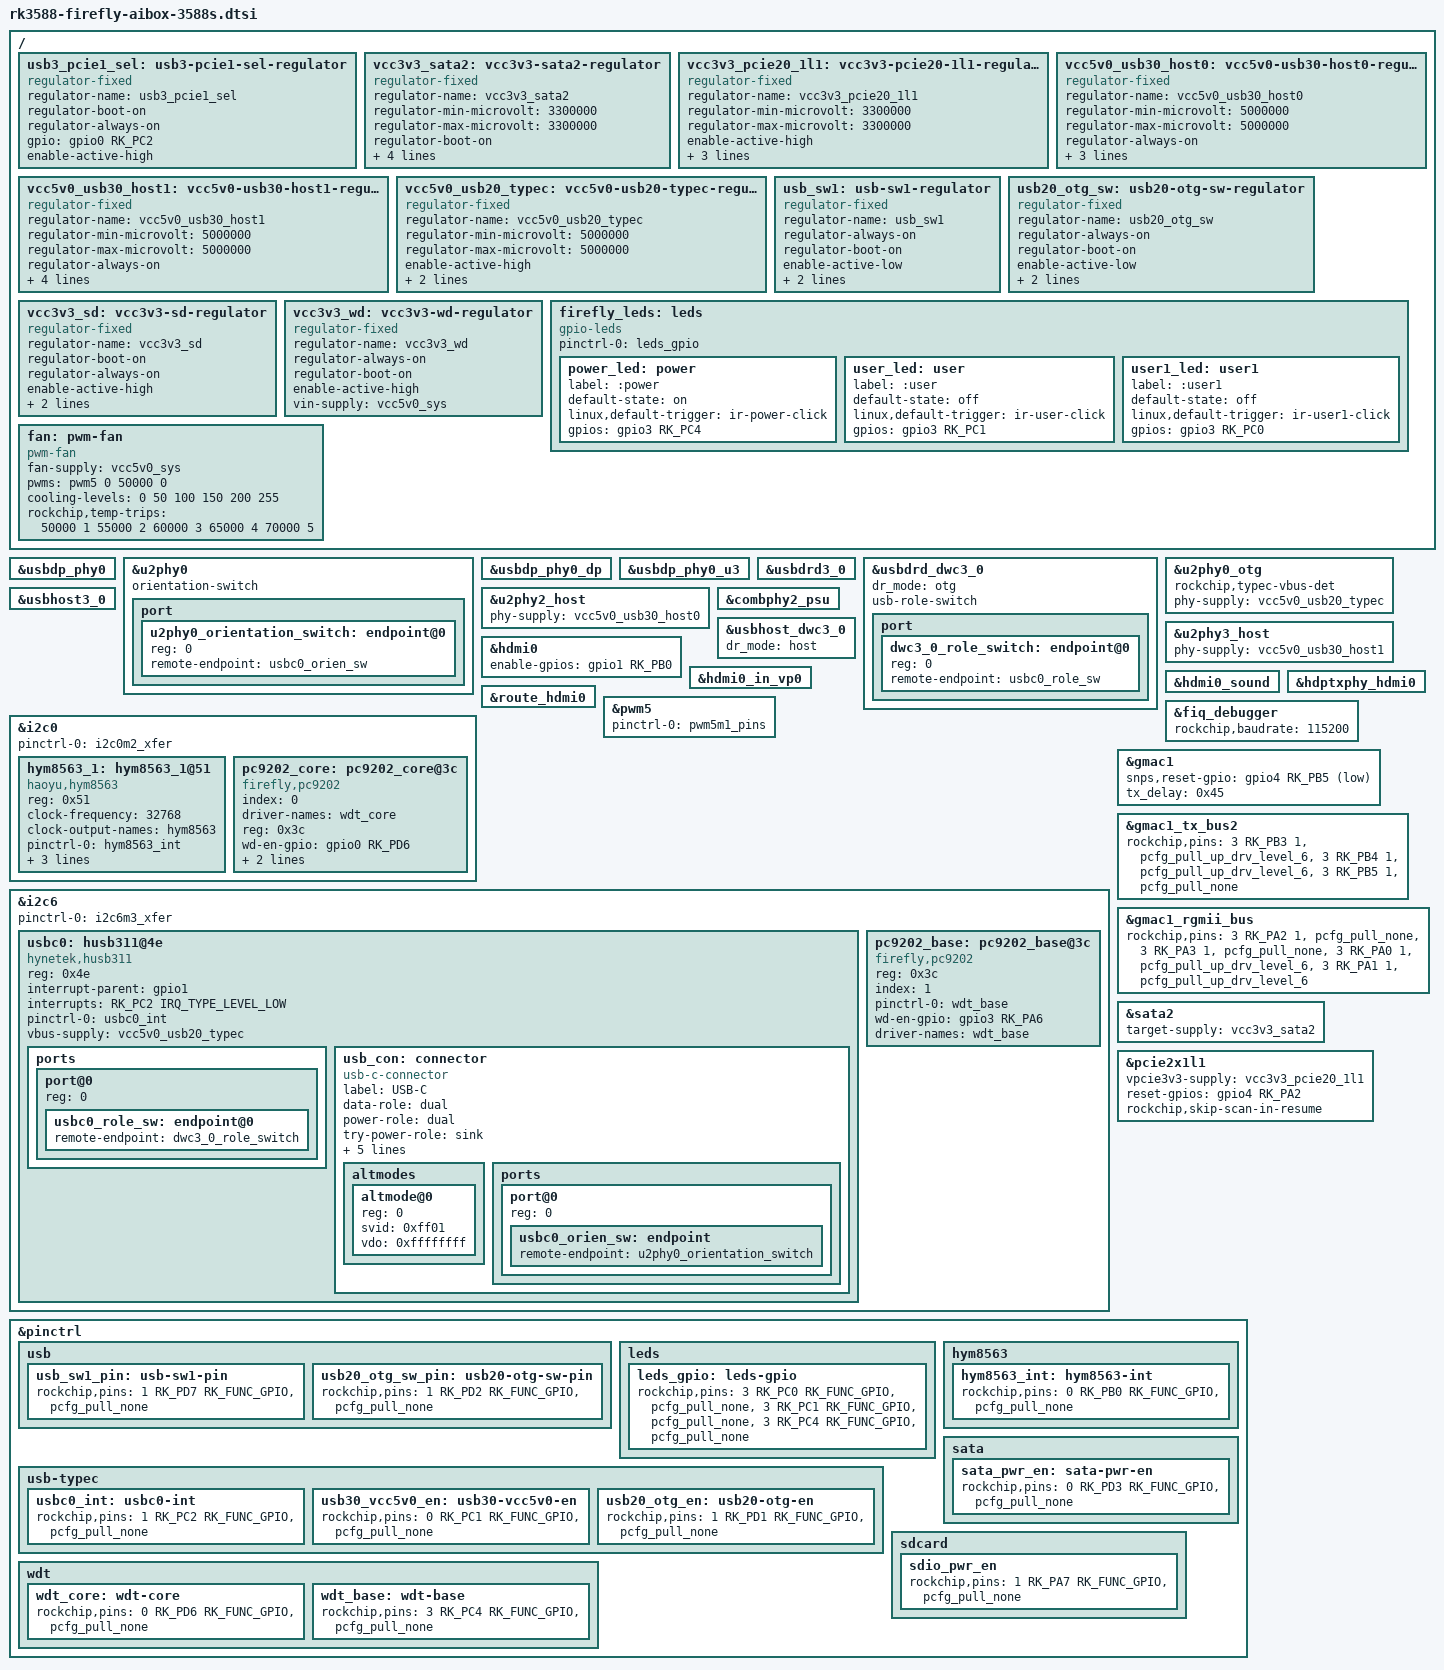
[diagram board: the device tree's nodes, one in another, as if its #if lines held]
// SPDX-License-Identifier: (GPL-2.0+ OR MIT)
/*
 * Copyright (c) 2021 Rockchip Electronics Co., Ltd.
 *
 */
 
#include "rk3588-firefly-common.dtsi"

/ {
	usb3_pcie1_sel: usb3-pcie1-sel-regulator {
		status = "okay";
		compatible = "regulator-fixed";
		regulator-name = "usb3_pcie1_sel";
		regulator-boot-on;
                regulator-always-on;
		gpio = <&gpio0 RK_PC2 GPIO_ACTIVE_HIGH>;

#if USB3_OR_M2_SLOT /* 1 = USB3 , 0 = M2_SLOT */
		enable-active-high;
#else
		enable-active-low;
#endif
	};

#if defined(FF_SATA2) && !defined(FF_PCIE2_1L1)
	vcc3v3_sata2: vcc3v3-sata2-regulator {
		status = "okay";
		compatible = "regulator-fixed";
		regulator-name = "vcc3v3_sata2";
		regulator-min-microvolt = <3300000>;
		regulator-max-microvolt = <3300000>;
		regulator-boot-on;
		enable-active-high;
		gpio = <&gpio0 RK_PD3 GPIO_ACTIVE_HIGH>;
		startup-delay-us = <5000>;
		vin-supply = <&vcc12v_dcin>;
	};
#endif

#if defined(FF_PCIE2_1L1) && !defined(FF_SATA2)
	vcc3v3_pcie20_1l1: vcc3v3-pcie20-1l1-regulator {
		status = "okay";
		compatible = "regulator-fixed";
		regulator-name = "vcc3v3_pcie20_1l1";
		regulator-min-microvolt = <3300000>;
		regulator-max-microvolt = <3300000>;
		enable-active-high;
		gpio = <&gpio0 RK_PD3 GPIO_ACTIVE_HIGH>;
		startup-delay-us = <5000>;
		vin-supply = <&vcc12v_dcin>;
	};
#endif

 	vcc5v0_usb30_host0: vcc5v0-usb30-host0-regulator {
  		compatible = "regulator-fixed";
                regulator-name = "vcc5v0_usb30_host0";
                regulator-min-microvolt = <5000000>;
                regulator-max-microvolt = <5000000>;
                regulator-always-on;
                regulator-boot-on;
                enable-active-high;
                pinctrl-names = "default";
		vin-supply = <&vcc5v0_usb30_host1>;
                status = "okay";
 	};

 	vcc5v0_usb30_host1: vcc5v0-usb30-host1-regulator {
  		compatible = "regulator-fixed";
                regulator-name = "vcc5v0_usb30_host1";
                regulator-min-microvolt = <5000000>;
                regulator-max-microvolt = <5000000>;
                regulator-always-on;
                regulator-boot-on;
                enable-active-high;
                gpio = <&gpio0 RK_PC1 GPIO_ACTIVE_HIGH>;
                pinctrl-names = "default";
                pinctrl-0 = <&usb30_vcc5v0_en>;
                status = "okay";
 	};

        vcc5v0_usb20_typec: vcc5v0-usb20-typec-regulator {
                compatible = "regulator-fixed";
                regulator-name = "vcc5v0_usb20_typec";
                regulator-min-microvolt = <5000000>;
                regulator-max-microvolt = <5000000>;
                enable-active-high;
                gpio = <&gpio1 RK_PD1 GPIO_ACTIVE_HIGH>;
                pinctrl-0 = <&usb20_otg_en>;
                status = "okay";
        };

        usb_sw1: usb-sw1-regulator {
		compatible = "regulator-fixed";
		regulator-name = "usb_sw1";
		regulator-always-on;
		regulator-boot-on;
		enable-active-low;
		gpio = <&gpio1 RK_PD7 GPIO_ACTIVE_HIGH>;
		pinctrl-0 = <&usb_sw1_pin>;
		status = "okay";
        };

        usb20_otg_sw: usb20-otg-sw-regulator {
		compatible = "regulator-fixed";
		regulator-name = "usb20_otg_sw";
		regulator-always-on;
		regulator-boot-on;
		enable-active-low;
		gpio = <&gpio1 RK_PD2 GPIO_ACTIVE_HIGH>;
		pinctrl-0 = <&usb20_otg_sw_pin>;
		status = "okay";
        };

#ifdef FF_SDCARD
        vcc3v3_sd: vcc3v3-sd-regulator {
                compatible = "regulator-fixed";
                regulator-name = "vcc3v3_sd";
                regulator-boot-on;
                regulator-always-on;
                enable-active-high;
                gpio = <&gpio1 RK_PA7 GPIO_ACTIVE_HIGH>;
                pinctrl-0 = <&sdio_pwr_en>;
                status = "okay";
        };
#endif

#ifdef FF_WATCHDOG
 	vcc3v3_wd: vcc3v3-wd-regulator {
  		compatible = "regulator-fixed";
                regulator-name = "vcc3v3_wd";
                regulator-always-on;
                regulator-boot-on;
                enable-active-high;
                pinctrl-names = "default";
		vin-supply = <&vcc5v0_sys>;
                status = "okay";
 	};
#endif

#ifdef FF_LEDS
/* led */
	firefly_leds: leds {
		status = "okay";
		compatible = "gpio-leds";
		pinctrl-names = "default";
		pinctrl-0 =<&leds_gpio>;

		power_led: power {
			label = ":power"; 
			default-state = "on";
			linux,default-trigger = "ir-power-click";
			gpios = <&gpio3 RK_PC4 GPIO_ACTIVE_HIGH>;//blue led
		};

		user_led: user {
			label = ":user"; 
			default-state = "off";
			linux,default-trigger = "ir-user-click";
			gpios = <&gpio3 RK_PC1 GPIO_ACTIVE_HIGH>;//red led
		};

		user1_led: user1 {
			label = ":user1"; 
			default-state = "off";
			linux,default-trigger = "ir-user1-click";
			gpios = <&gpio3 RK_PC0 GPIO_ACTIVE_HIGH>;//green led
		};
	};
#endif

#ifdef FF_FAN
 	fan: pwm-fan {
		compatible = "pwm-fan";
		#cooling-cells = <2>;
		fan-supply = <&vcc5v0_sys>;
		pwms = <&pwm5 0 50000 0>;
		cooling-levels = <0 50 100 150 200 255>;
		rockchip,temp-trips = <
		    50000   1
		    55000   2
		    60000   3
		    65000   4
		    70000   5
		>;
	};
#endif
};

#if TYPEC_OTG_20

&usbdp_phy0 {
	status = "okay";
};

&u2phy0 {
	status = "okay";
	orientation-switch;
	port {
		#address-cells = <1>;
		#size-cells = <0>;
		u2phy0_orientation_switch: endpoint@0 {
			reg = <0>;
			remote-endpoint = <&usbc0_orien_sw>;
		};
	};
};

&usbdp_phy0_dp {
	status = "okay";
};

&usbdp_phy0_u3 {
	status = "okay";
};

&usbdrd3_0 {
        status = "okay";
};

&usbdrd_dwc3_0 {
	status = "okay";
	dr_mode = "otg";
	usb-role-switch;
        port {
		#address-cells = <1>;
		#size-cells = <0>;
		dwc3_0_role_switch: endpoint@0 {
			reg = <0>;
			remote-endpoint = <&usbc0_role_sw>;
		};
	};
};


&u2phy0_otg { 
	status = "okay";
	rockchip,typec-vbus-det;
	phy-supply  = <&vcc5v0_usb20_typec>;
}; 

#else

&vcc5v0_usb20_typec {
	regulator-always-on;
	regulator-boot-on;
	status = "okay";
};

&usbdp_phy0_dp {
	status = "okay";
};

&usbdp_phy0_u3 {
	status = "okay";
};

&usbdrd3_0 {
        status = "okay";
};

&usbdrd_dwc3_0 {
	status = "okay";
	dr_mode = "host";
};

&u2phy0 {
	status = "okay";
};

&u2phy0_otg { 
	rockchip,vbus-always-on;
	status = "okay";
}; 

&usbdp_phy0 {
	status = "okay";
};
#endif

#ifdef FF_USB20_HOST0
&u2phy2_host {
	phy-supply  = <&vcc5v0_usb30_host0>;
	status = "okay";
};
#endif



#ifdef FF_USB30 // Type-C1 to Type-A
&combphy2_psu {
	status = "okay"; // USB3.1/SATA/PCIe Combo PHY
};

&usbhost3_0 {
	status = "okay";
};

&usbhost_dwc3_0 {
        dr_mode = "host";
        status = "okay";
};

&u2phy3_host {
	phy-supply  = <&vcc5v0_usb30_host1>;
	status = "okay";
};
#endif

#ifdef FF_HDMI0
/* hdmi0 */
&hdmi0 {
	enable-gpios = <&gpio1 RK_PB0 GPIO_ACTIVE_HIGH>;
	status = "okay";
};

&hdmi0_in_vp0 {
	status = "okay";
};

&hdmi0_sound {
	status = "okay";
};

&hdptxphy_hdmi0 {
	status = "okay";
};

&route_hdmi0{
	status = "okay";
};
#endif

#ifdef FF_FAN
&pwm5 {
	pinctrl-0 = <&pwm5m1_pins>;
	status = "okay";
};
#endif

//debug 115200
&fiq_debugger{
	rockchip,baudrate = <115200>;  /* Only 115200 and 1500000 */
};

&i2c0 {
	status = "okay";
	pinctrl-0 = <&i2c0m2_xfer>;

#ifdef FF_RTC
	/* rtc */
	hym8563_1: hym8563_1@51 {
		compatible = "haoyu,hym8563";
		reg = <0x51>;
		#clock-cells = <0>;
		clock-frequency = <32768>;
		clock-output-names = "hym8563";
		pinctrl-names = "default";
		pinctrl-0 = <&hym8563_int>;
		interrupt-parent = <&gpio0>;
		interrupts = <RK_PB0 IRQ_TYPE_LEVEL_LOW>;
		wakeup-source;
		status = "okay";
	};
#endif

#ifdef FF_WATCHDOG
	/* watch dog on core*/
	pc9202_core: pc9202_core@3c {
		status = "okay";
		compatible = "firefly,pc9202";
		index = <0>;
		driver-names = "wdt_core";
		reg = <0x3c>;
		wd-en-gpio = <&gpio0 RK_PD6 GPIO_ACTIVE_HIGH>;
		pinctrl-0 = <&wdt_core>;
		pinctrl-name = "wdt_core";
	};
};
#endif


&i2c6 {
	status = "okay";
	pinctrl-names = "default";
	pinctrl-0 = <&i2c6m3_xfer>;
#if TYPEC_OTG_20
	usbc0: husb311@4e {
		compatible = "hynetek,husb311";
		reg = <0x4e>;
		interrupt-parent = <&gpio1>;
		interrupts = <RK_PC2 IRQ_TYPE_LEVEL_LOW>;
		pinctrl-names = "default";
		pinctrl-0 = <&usbc0_int>;
		vbus-supply = <&vcc5v0_usb20_typec>;
		status = "okay";

		ports {
			#address-cells = <1>;
			#size-cells = <0>;

			port@0 {
				reg = <0>;
				usbc0_role_sw: endpoint@0 {
					remote-endpoint = <&dwc3_0_role_switch>;
				};
			};
		};

		usb_con: connector {
			compatible = "usb-c-connector";
			label = "USB-C";
			data-role = "dual";
			power-role = "dual";
			try-power-role = "sink";
			op-sink-microwatt = <1000000>;
			sink-pdos =
				<PDO_FIXED(5000, 1000, PDO_FIXED_USB_COMM)>;
			source-pdos =
				<PDO_FIXED(5000, 3000, PDO_FIXED_USB_COMM)>;

			altmodes {
				#address-cells = <1>;
				#size-cells = <0>;

				altmode@0 {
					reg = <0>;
					svid = <0xff01>;
					vdo = <0xffffffff>;
				};
			};

			ports {
				#address-cells = <1>;
				#size-cells = <0>;

				port@0 {
					reg = <0>;
					usbc0_orien_sw: endpoint {
						remote-endpoint = <&u2phy0_orientation_switch>;
					};
				};
/*
				port@1 {
					reg = <1>;
					dp_altmode_mux: endpoint {
						remote-endpoint = <&usbdp_phy0_dp_altmode_mux>;
					};
				};
*/
			};
		};
	};
#endif

#ifdef FF_WATCHDOG
	// watch dog on mother base
	pc9202_base: pc9202_base@3c {
		status = "okay";
		compatible = "firefly,pc9202";
		reg = <0x3c>;
		index = <1>;
		pinctrl-names = "wdt_base";
		pinctrl-0 =<&wdt_base>;
		wd-en-gpio = <&gpio3 RK_PA6 GPIO_ACTIVE_HIGH>; 
		driver-names = "wdt_base";
	};
#endif
};

#ifdef FF_GMAC1
/* gmac1 */
&gmac1 {
	snps,reset-gpio = <&gpio4 RK_PB5 GPIO_ACTIVE_LOW>;
	tx_delay = <0x45>;
	status = "okay";
};

&gmac1_tx_bus2{
	rockchip,pins =
		/* gmac1_txd0 */
		<3 RK_PB3 1 &pcfg_pull_up_drv_level_6>,
		/* gmac1_txd1 */
		<3 RK_PB4 1 &pcfg_pull_up_drv_level_6>,
		/* gmac1_txen */
		<3 RK_PB5 1 &pcfg_pull_none>;
};

&gmac1_rgmii_bus{
	rockchip,pins =
		/* gmac1_rxd2 */
		<3 RK_PA2 1 &pcfg_pull_none>,
		/* gmac1_rxd3 */
		<3 RK_PA3 1 &pcfg_pull_none>,
		/* gmac1_txd2 */
		<3 RK_PA0 1 &pcfg_pull_up_drv_level_6>,
		/* gmac1_txd3 */
		<3 RK_PA1 1 &pcfg_pull_up_drv_level_6>;
};
#endif

#if defined(FF_SATA2) && !defined(FF_PCIE2_1L1)
&combphy2_psu {
	status = "okay";
};

&sata2 {
	status = "okay";
	target-supply = <&vcc3v3_sata2>;
};
#endif

#if defined(FF_PCIE2_1L1) && !defined(FF_SATA2)
&combphy2_psu {
	status = "okay";
};

&pcie2x1l1 {
	vpcie3v3-supply = <&vcc3v3_pcie20_1l1>;
	reset-gpios = <&gpio4 RK_PA2 GPIO_ACTIVE_HIGH>;
	rockchip,skip-scan-in-resume;
	status = "okay";
};
#endif


/* pinctrl */
&pinctrl {

	usb {
		usb_sw1_pin: usb-sw1-pin {
			rockchip,pins = <1 RK_PD7 RK_FUNC_GPIO &pcfg_pull_none>;
		};

		usb20_otg_sw_pin: usb20-otg-sw-pin {
			rockchip,pins =	<1 RK_PD2 RK_FUNC_GPIO &pcfg_pull_none>;
		};
 	};

#ifdef FF_LEDS
	leds {
		leds_gpio: leds-gpio {
			/* led_power */
			rockchip,pins = <3 RK_PC0 RK_FUNC_GPIO &pcfg_pull_none>,
					<3 RK_PC1 RK_FUNC_GPIO &pcfg_pull_none>,
					<3 RK_PC4 RK_FUNC_GPIO &pcfg_pull_none>;
		};
 	};
#endif

#ifdef FF_RTC
 	hym8563 {
		hym8563_int: hym8563-int {
			rockchip,pins = <0 RK_PB0 RK_FUNC_GPIO &pcfg_pull_none>;
		};
	};
#endif

#ifdef FF_TYPEC_FULL
	usb-typec { 

		usbc0_int: usbc0-int { 
			rockchip,pins = <1 RK_PC2 RK_FUNC_GPIO &pcfg_pull_none>; 
		}; 

  		usb30_vcc5v0_en: usb30-vcc5v0-en {
   			rockchip,pins = <0 RK_PC1 RK_FUNC_GPIO &pcfg_pull_none>;
  		};

                usb20_otg_en:  usb20-otg-en {
   			rockchip,pins = <1 RK_PD1 RK_FUNC_GPIO &pcfg_pull_none>;
		};

	};
#endif

	sata {
		sata_pwr_en: sata-pwr-en { 
			rockchip,pins = <0 RK_PD3 RK_FUNC_GPIO &pcfg_pull_none>; 
		}; 
	};

#ifdef FF_WATCHDOG
	wdt {
		wdt_core: wdt-core {
			rockchip,pins = <0 RK_PD6 RK_FUNC_GPIO &pcfg_pull_none>;
		};

		wdt_base: wdt-base {
			rockchip,pins = <3 RK_PC4 RK_FUNC_GPIO &pcfg_pull_none>;
		};
	};
#endif

#ifdef FF_SDCARD
	sdcard {
		sdio_pwr_en: sdio_pwr_en {
			rockchip,pins = <1 RK_PA7 RK_FUNC_GPIO &pcfg_pull_none>;
		};
	};
#endif
};
